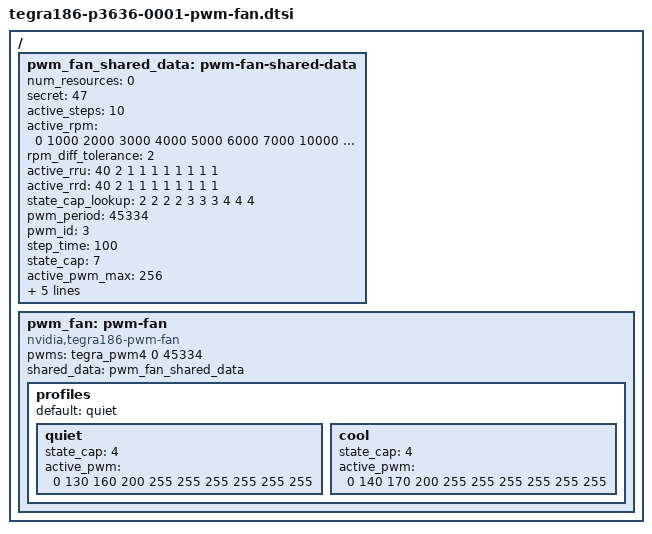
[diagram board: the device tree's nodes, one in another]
// SPDX-License-Identifier: GPL-2.0
#include <dt-bindings/pwm/pwm.h>

/ {
	pwm_fan_shared_data: pwm-fan-shared-data {
		status = "okay";
		num_resources = <0>;
		secret = <47>;
		active_steps = <10>;
		active_rpm = <0 1000 2000 3000 4000 5000 6000 7000 10000 11000>;
		rpm_diff_tolerance = <2>;
		active_rru = <40 2 1 1 1 1 1 1 1 1>;
		active_rrd = <40 2 1 1 1 1 1 1 1 1>;
		state_cap_lookup = <2 2 2 2 3 3 3 4 4 4>;
		pwm_period = <45334>;
		pwm_id = <3>;
		step_time = <100>;
		state_cap = <7>;
		active_pwm_max = <256>;
		tach_period = <1000>;
		pwm_gpio = <&gpio_aon TEGRA_AON_GPIO(V, 6) GPIO_ACTIVE_LOW>;
		pwm_polarity = <PWM_POLARITY_NORMAL>;
		suspend_state = <0>;
	};

	pwm_fan: pwm-fan {
		status = "okay";
		compatible = "nvidia,tegra186-pwm-fan";
		#pwm-cells = <1>;
		pwms = <&tegra_pwm4 0 45334>;
		shared_data = <&pwm_fan_shared_data>;

		profiles {
			default = "quiet";

			quiet {
				state_cap = <4>;
				active_pwm = <0 130 160 200 255 255 255 255 255 255>;
			};

			cool {
				state_cap = <4>;
				active_pwm = <0 140 170 200 255 255 255 255 255 255>;
			};
		};
	};
};
